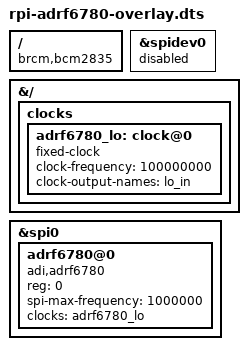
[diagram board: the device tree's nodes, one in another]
// SPDX-License-Identifier: GPL-2.0
/dts-v1/;
/plugin/;

/ {
	compatible = "brcm,bcm2835";
};

&spidev0 {
	status = "disabled";
};

&{/} {
	clocks {
		adrf6780_lo: clock@0 {
			compatible = "fixed-clock";

			clock-frequency = <100000000>;
			clock-output-names = "lo_in";
			#clock-cells = <0>;
		};
	};
};

&spi0 {
	#address-cells = <1>;
	#size-cells = <0>;
	status = "okay";

	adrf6780@0 {
		compatible = "adi,adrf6780";
		reg = <0>;
		spi-max-frequency = <1000000>;
		clocks = <&adrf6780_lo>;
		clock-names = "lo_in";
	};
};
